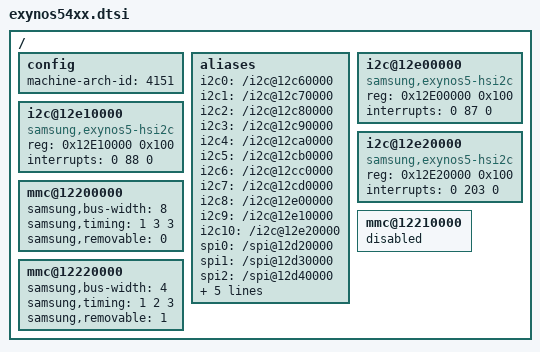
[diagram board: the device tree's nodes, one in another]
/*
 * SAMSUNG Peach board device tree source
 *
 * Copyright (c) 2013 Samsung Electronics Co., Ltd.
 *		http://www.samsung.com
 *
 * This program is free software; you can redistribute it and/or modify
 * it under the terms of the GNU General Public License version 2 as
 * published by the Free Software Foundation.
*/

/include/ "exynos5.dtsi"
/ {
	config {
		machine-arch-id = <4151>;
	};

	aliases {
		i2c0 = "/i2c@12c60000";
		i2c1 = "/i2c@12c70000";
		i2c2 = "/i2c@12c80000";
		i2c3 = "/i2c@12c90000";
		i2c4 = "/i2c@12ca0000";
		i2c5 = "/i2c@12cb0000";
		i2c6 = "/i2c@12cc0000";
		i2c7 = "/i2c@12cd0000";
		i2c8 = "/i2c@12e00000";
		i2c9 = "/i2c@12e10000";
		i2c10 = "/i2c@12e20000";
		spi0 = "/spi@12d20000";
		spi1 = "/spi@12d30000";
		spi2 = "/spi@12d40000";
		spi3 = "/spi@131a0000";
		spi4 = "/spi@131b0000";
		mmc0 = "/mmc@12200000";
		mmc1 = "/mmc@12210000";
		mmc2 = "/mmc@12220000";
	};

	i2c@12e00000 {
		#address-cells = <1>;
		#size-cells = <0>;
		compatible = "samsung,exynos5-hsi2c";
		reg = <0x12E00000 0x100>;
		interrupts = <0 87 0>;
	};

	i2c@12e10000 {
		#address-cells = <1>;
		#size-cells = <0>;
		compatible = "samsung,exynos5-hsi2c";
		reg = <0x12E10000 0x100>;
		interrupts = <0 88 0>;
	};

	i2c@12e20000 {
		#address-cells = <1>;
		#size-cells = <0>;
		compatible = "samsung,exynos5-hsi2c";
		reg = <0x12E20000 0x100>;
		interrupts = <0 203 0>;
	};

	mmc@12200000 {
		samsung,bus-width = <8>;
		samsung,timing = <1 3 3>;
		samsung,removable = <0>;
	};

	mmc@12210000 {
		status = "disabled";
	};

	mmc@12220000 {
		samsung,bus-width = <4>;
		samsung,timing = <1 2 3>;
		samsung,removable = <1>;
	};
};
